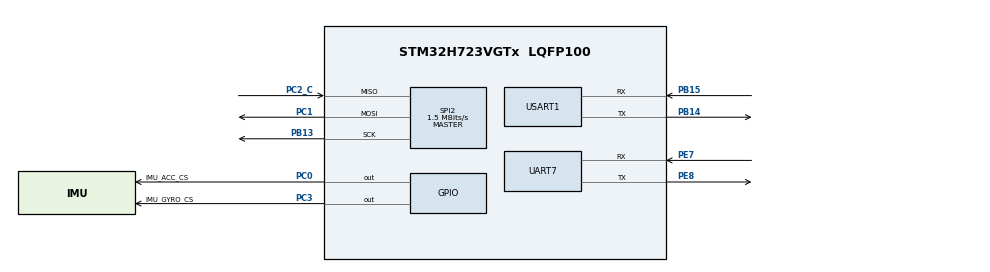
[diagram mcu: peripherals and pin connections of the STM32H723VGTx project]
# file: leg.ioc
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CORTEX_M7.default_mode_Activation=1
Mcu.Family=STM32H7
Mcu.Name=STM32H723VGTx
Mcu.Package=LQFP100
NVIC.PriorityGroup=NVIC_PRIORITYGROUP_4
NVIC.USART1_IRQn=true\:5\:0\:false\:false\:true\:true\:true\:true
PB13.Mode=Full_Duplex_Master
PB13.Signal=SPI2_SCK
PB14.Mode=Asynchronous
PB14.Signal=USART1_TX
PB15.Mode=Asynchronous
PB15.Signal=USART1_RX
PC1.Mode=Full_Duplex_Master
PC1.Signal=SPI2_MOSI
PC2_C.Mode=Full_Duplex_Master
PC2_C.Signal=SPI2_MISO
PE7.Mode=Asynchronous
PE7.Signal=UART7_RX
PE8.Mode=Asynchronous
PE8.Signal=UART7_TX
PH0-OSC_IN.Mode=HSE-External-Oscillator
PH0-OSC_IN.Signal=RCC_OSC_IN
PH1-OSC_OUT.Mode=HSE-External-Oscillator
PH1-OSC_OUT.Signal=RCC_OSC_OUT
ProjectManager.HeapSize=0x200
ProjectManager.StackSize=0x400
ProjectManager.TargetToolchain=CMake
RCC.ADCFreq_Value=48375000
RCC.APB1Freq_Value=96000000
RCC.APB2Freq_Value=96000000
RCC.APB3Freq_Value=96000000
RCC.APB4Freq_Value=96000000
RCC.CortexFreq_Value=192000000
RCC.D1PPRE=RCC_APB3_DIV2
RCC.D2PPRE1=RCC_APB1_DIV2
RCC.D2PPRE2=RCC_APB2_DIV2
RCC.D3PPRE=RCC_APB4_DIV2
RCC.DIVM1=2
RCC.DIVN1=16
RCC.DIVP1=1
RCC.DIVQ1=4
RCC.HCLKFreq_Value=192000000
RCC.HSE_VALUE=24000000
RCC.PLLFRACN=0
RCC.PLLSourceVirtual=RCC_PLLSOURCE_HSE
RCC.SYSCLKFreq_VALUE=192000000
RCC.SYSCLKSource=RCC_SYSCLKSOURCE_PLLCLK
RCC.USBFreq_Value=48000000
SPI2.BaudRatePrescaler=SPI_BAUDRATEPRESCALER_32
SPI2.CLKPhase=SPI_PHASE_2EDGE
SPI2.CLKPolarity=SPI_POLARITY_HIGH
SPI2.CalculateBaudRate=1.5 MBits/s
SPI2.DataSize=SPI_DATASIZE_8BIT
SPI2.Direction=SPI_DIRECTION_2LINES
SPI2.Mode=SPI_MODE_MASTER
SPI2.VirtualType=VM_MASTER
USART1.VirtualMode-Asynchronous=VM_ASYNC
VP_MEMORYMAP_VS_MEMORYMAP.Mode=CurAppReg
VP_SYS_VS_tim6.Mode=TIM6
board=custom
FREERTOS.configENABLE_FPU=1
FREERTOS.configSUPPORT_STATIC_ALLOCATION=1
FREERTOS.configSUPPORT_DYNAMIC_ALLOCATION=0
FREERTOS.configCHECK_FOR_STACK_OVERFLOW=2
FREERTOS.configUSE_MALLOC_FAILED_HOOK=1
VP_FREERTOS_VS_CMSIS_V2.Mode=CMSIS_V2
PC0.Signal=GPIO_Output
PC0.GPIO_Label=IMU_ACC_CS
PC0.PinState=GPIO_PIN_SET
PC3.Signal=GPIO_Output
PC3.GPIO_Label=IMU_GYRO_CS
PC3.PinState=GPIO_PIN_SET

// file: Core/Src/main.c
/* USER CODE BEGIN Header */
/**
  ******************************************************************************
  * @file           : main.c
  * @brief          : Main program body
  ******************************************************************************
  * @attention
  *
  * Copyright (c) 2026 STMicroelectronics.
  * All rights reserved.
  *
  * This software is licensed under terms that can be found in the LICENSE file
  * in the root directory of this software component.
  * If no LICENSE file comes with this software, it is provided AS-IS.
  *
  ******************************************************************************
  */
/* USER CODE END Header */
#include "main.h"

/* USER CODE BEGIN Includes */
#include "cmsis_os2.h"
#include "app.h"

/* USER CODE END Includes */

SPI_HandleTypeDef hspi2;

UART_HandleTypeDef huart7;
UART_HandleTypeDef huart1;

void SystemClock_Config(void);
static void MPU_Config(void);
static void MX_GPIO_Init(void);
static void MX_SPI2_Init(void);
static void MX_UART7_Init(void);
static void MX_USART1_UART_Init(void);

int main(void)
{

  /* MPU Configuration--------------------------------------------------------*/
  MPU_Config();

  /* MCU Configuration--------------------------------------------------------*/

  /* Reset of all peripherals, Initializes the Flash interface and the Systick. */
  HAL_Init();

  /* Configure the system clock */
  SystemClock_Config();

  /* Initialize all configured peripherals */
  MX_GPIO_Init();
  MX_SPI2_Init();
  MX_UART7_Init();
  MX_USART1_UART_Init();
  /* USER CODE BEGIN 2 */
  if (osKernelInitialize() != osOK) Error_Handler();
  App_Init();
  if (osKernelStart() != osOK) Error_Handler();

  /* USER CODE END 2 */

  /* Infinite loop */
  while (1)
  {

  }
}

void SystemClock_Config(void)
{
  RCC_OscInitTypeDef RCC_OscInitStruct = {0};
  RCC_ClkInitTypeDef RCC_ClkInitStruct = {0};

  /** Supply configuration update enable
  */
  HAL_PWREx_ConfigSupply(PWR_LDO_SUPPLY);

  /** Configure the main internal regulator output voltage
  */
  __HAL_PWR_VOLTAGESCALING_CONFIG(PWR_REGULATOR_VOLTAGE_SCALE1);

  while(!__HAL_PWR_GET_FLAG(PWR_FLAG_VOSRDY)) {}

  /** Initializes the RCC Oscillators according to the specified parameters
  * in the RCC_OscInitTypeDef structure.
  */
  RCC_OscInitStruct.OscillatorType = RCC_OSCILLATORTYPE_HSE;
  RCC_OscInitStruct.HSEState = RCC_HSE_ON;
  RCC_OscInitStruct.PLL.PLLState = RCC_PLL_ON;
  RCC_OscInitStruct.PLL.PLLSource = RCC_PLLSOURCE_HSE;
  RCC_OscInitStruct.PLL.PLLM = 2;
  RCC_OscInitStruct.PLL.PLLN = 16;
  RCC_OscInitStruct.PLL.PLLP = 1;
  RCC_OscInitStruct.PLL.PLLQ = 4;
  RCC_OscInitStruct.PLL.PLLR = 2;
  RCC_OscInitStruct.PLL.PLLRGE = RCC_PLL1VCIRANGE_3;
  RCC_OscInitStruct.PLL.PLLVCOSEL = RCC_PLL1VCOWIDE;
  RCC_OscInitStruct.PLL.PLLFRACN = 0;
  if (HAL_RCC_OscConfig(&RCC_OscInitStruct) != HAL_OK)
  {
    Error_Handler();
  }

  /** Initializes the CPU, AHB and APB buses clocks
  */
  RCC_ClkInitStruct.ClockType = RCC_CLOCKTYPE_HCLK|RCC_CLOCKTYPE_SYSCLK
                              |RCC_CLOCKTYPE_PCLK1|RCC_CLOCKTYPE_PCLK2
                              |RCC_CLOCKTYPE_D3PCLK1|RCC_CLOCKTYPE_D1PCLK1;
  RCC_ClkInitStruct.SYSCLKSource = RCC_SYSCLKSOURCE_PLLCLK;
  RCC_ClkInitStruct.SYSCLKDivider = RCC_SYSCLK_DIV1;
  RCC_ClkInitStruct.AHBCLKDivider = RCC_HCLK_DIV1;
  RCC_ClkInitStruct.APB3CLKDivider = RCC_APB3_DIV2;
  RCC_ClkInitStruct.APB1CLKDivider = RCC_APB1_DIV2;
  RCC_ClkInitStruct.APB2CLKDivider = RCC_APB2_DIV2;
  RCC_ClkInitStruct.APB4CLKDivider = RCC_APB4_DIV2;

  if (HAL_RCC_ClockConfig(&RCC_ClkInitStruct, FLASH_LATENCY_2) != HAL_OK)
  {
    Error_Handler();
  }
}

static void MX_SPI2_Init(void)
{

  /* SPI2 parameter configuration*/
  hspi2.Instance = SPI2;
  hspi2.Init.Mode = SPI_MODE_MASTER;
  hspi2.Init.Direction = SPI_DIRECTION_2LINES;
  hspi2.Init.DataSize = SPI_DATASIZE_8BIT;
  hspi2.Init.CLKPolarity = SPI_POLARITY_HIGH;
  hspi2.Init.CLKPhase = SPI_PHASE_2EDGE;
  hspi2.Init.NSS = SPI_NSS_SOFT;
  hspi2.Init.BaudRatePrescaler = SPI_BAUDRATEPRESCALER_32;
  hspi2.Init.FirstBit = SPI_FIRSTBIT_MSB;
  hspi2.Init.TIMode = SPI_TIMODE_DISABLE;
  hspi2.Init.CRCCalculation = SPI_CRCCALCULATION_DISABLE;
  hspi2.Init.CRCPolynomial = 0x0;
  hspi2.Init.NSSPMode = SPI_NSS_PULSE_ENABLE;
  hspi2.Init.NSSPolarity = SPI_NSS_POLARITY_LOW;
  hspi2.Init.FifoThreshold = SPI_FIFO_THRESHOLD_01DATA;
  hspi2.Init.TxCRCInitializationPattern = SPI_CRC_INITIALIZATION_ALL_ZERO_PATTERN;
  hspi2.Init.RxCRCInitializationPattern = SPI_CRC_INITIALIZATION_ALL_ZERO_PATTERN;
  hspi2.Init.MasterSSIdleness = SPI_MASTER_SS_IDLENESS_00CYCLE;
  hspi2.Init.MasterInterDataIdleness = SPI_MASTER_INTERDATA_IDLENESS_00CYCLE;
  hspi2.Init.MasterReceiverAutoSusp = SPI_MASTER_RX_AUTOSUSP_DISABLE;
  hspi2.Init.MasterKeepIOState = SPI_MASTER_KEEP_IO_STATE_DISABLE;
  hspi2.Init.IOSwap = SPI_IO_SWAP_DISABLE;
  if (HAL_SPI_Init(&hspi2) != HAL_OK)
  {
    Error_Handler();
  }

}

static void MX_UART7_Init(void)
{

  huart7.Instance = UART7;
  huart7.Init.BaudRate = 115200;
  huart7.Init.WordLength = UART_WORDLENGTH_8B;
  huart7.Init.StopBits = UART_STOPBITS_1;
  huart7.Init.Parity = UART_PARITY_NONE;
  huart7.Init.Mode = UART_MODE_TX_RX;
  huart7.Init.HwFlowCtl = UART_HWCONTROL_NONE;
  huart7.Init.OverSampling = UART_OVERSAMPLING_16;
  huart7.Init.OneBitSampling = UART_ONE_BIT_SAMPLE_DISABLE;
  huart7.Init.ClockPrescaler = UART_PRESCALER_DIV1;
  huart7.AdvancedInit.AdvFeatureInit = UART_ADVFEATURE_NO_INIT;
  if (HAL_UART_Init(&huart7) != HAL_OK)
  {
    Error_Handler();
  }
  if (HAL_UARTEx_SetTxFifoThreshold(&huart7, UART_TXFIFO_THRESHOLD_1_8) != HAL_OK)
  {
    Error_Handler();
  }
  if (HAL_UARTEx_SetRxFifoThreshold(&huart7, UART_RXFIFO_THRESHOLD_1_8) != HAL_OK)
  {
    Error_Handler();
  }
  if (HAL_UARTEx_DisableFifoMode(&huart7) != HAL_OK)
  {
    Error_Handler();
  }

}

static void MX_USART1_UART_Init(void)
{

  huart1.Instance = USART1;
  huart1.Init.BaudRate = 115200;
  huart1.Init.WordLength = UART_WORDLENGTH_8B;
  huart1.Init.StopBits = UART_STOPBITS_1;
  huart1.Init.Parity = UART_PARITY_NONE;
  huart1.Init.Mode = UART_MODE_TX_RX;
  huart1.Init.HwFlowCtl = UART_HWCONTROL_NONE;
  huart1.Init.OverSampling = UART_OVERSAMPLING_16;
  huart1.Init.OneBitSampling = UART_ONE_BIT_SAMPLE_DISABLE;
  huart1.Init.ClockPrescaler = UART_PRESCALER_DIV1;
  huart1.AdvancedInit.AdvFeatureInit = UART_ADVFEATURE_NO_INIT;
  if (HAL_UART_Init(&huart1) != HAL_OK)
  {
    Error_Handler();
  }
  if (HAL_UARTEx_SetTxFifoThreshold(&huart1, UART_TXFIFO_THRESHOLD_1_8) != HAL_OK)
  {
    Error_Handler();
  }
  if (HAL_UARTEx_SetRxFifoThreshold(&huart1, UART_RXFIFO_THRESHOLD_1_8) != HAL_OK)
  {
    Error_Handler();
  }
  if (HAL_UARTEx_DisableFifoMode(&huart1) != HAL_OK)
  {
    Error_Handler();
  }

}

static void MX_GPIO_Init(void)
{

  /* GPIO Ports Clock Enable */
  __HAL_RCC_GPIOH_CLK_ENABLE();
  __HAL_RCC_GPIOC_CLK_ENABLE();
  __HAL_RCC_GPIOE_CLK_ENABLE();
  __HAL_RCC_GPIOB_CLK_ENABLE();

  /* USER CODE BEGIN MX_GPIO_Init_2 */
  /* DM02 BMI088: ACC CS PC0, GYRO CS PC3, inactive high. */
  HAL_GPIO_WritePin(GPIOC, GPIO_PIN_0 | GPIO_PIN_3, GPIO_PIN_SET);
  GPIO_InitTypeDef imu_cs = {0};
  imu_cs.Pin = GPIO_PIN_0 | GPIO_PIN_3;
  imu_cs.Mode = GPIO_MODE_OUTPUT_PP;
  imu_cs.Pull = GPIO_NOPULL;
  imu_cs.Speed = GPIO_SPEED_FREQ_HIGH;
  HAL_GPIO_Init(GPIOC, &imu_cs);

  /* USER CODE END MX_GPIO_Init_2 */
}

 /* MPU Configuration */

void MPU_Config(void)
{
  MPU_Region_InitTypeDef MPU_InitStruct = {0};

  /* Disables the MPU */
  HAL_MPU_Disable();

  /** Initializes and configures the Region and the memory to be protected
  */
  MPU_InitStruct.Enable = MPU_REGION_ENABLE;
  MPU_InitStruct.Number = MPU_REGION_NUMBER0;
  MPU_InitStruct.BaseAddress = 0x0;
  MPU_InitStruct.Size = MPU_REGION_SIZE_4GB;
  MPU_InitStruct.SubRegionDisable = 0x87;
  MPU_InitStruct.TypeExtField = MPU_TEX_LEVEL0;
  MPU_InitStruct.AccessPermission = MPU_REGION_NO_ACCESS;
  MPU_InitStruct.DisableExec = MPU_INSTRUCTION_ACCESS_DISABLE;
  MPU_InitStruct.IsShareable = MPU_ACCESS_SHAREABLE;
  MPU_InitStruct.IsCacheable = MPU_ACCESS_NOT_CACHEABLE;
  MPU_InitStruct.IsBufferable = MPU_ACCESS_NOT_BUFFERABLE;

  HAL_MPU_ConfigRegion(&MPU_InitStruct);
  /* Enables the MPU */
  HAL_MPU_Enable(MPU_PRIVILEGED_DEFAULT);

}

void Error_Handler(void)
{
  __disable_irq();
  while (1)
  {
  }
}
